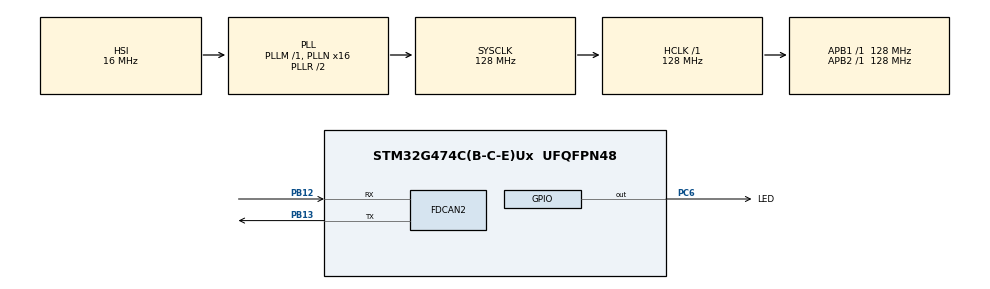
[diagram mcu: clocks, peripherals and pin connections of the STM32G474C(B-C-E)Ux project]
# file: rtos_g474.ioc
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FDCAN2.AutoRetransmission=ENABLE
FDCAN2.CalculateBaudRateNominal=1000000
FDCAN2.CalculateTimeBitNominal=1000
FDCAN2.CalculateTimeQuantumNominal=7.8125
FDCAN2.DataPrescaler=2
FDCAN2.DataSyncJumpWidth=6
FDCAN2.DataTimeSeg1=25
FDCAN2.DataTimeSeg2=6
FDCAN2.FrameFormat=FDCAN_FRAME_FD_BRS
FDCAN2.Mode=FDCAN_MODE_NORMAL
FDCAN2.NominalPrescaler=1
FDCAN2.NominalSyncJumpWidth=25
FDCAN2.NominalTimeSeg1=102
FDCAN2.NominalTimeSeg2=25
FREERTOS.Tasks01=defaultTask,24,1024,StartDefaultTask,Default,NULL,Dynamic,NULL,NULL;CANTransmitTask,24,1024,CANTransmit,Default,NULL,Static,CANTransmitTaskBuffer,CANTransmitTaskControlBlock
FREERTOS.Timers01=EnableCANTx,EnableCANTxCallback,osTimerPeriodic,Default,NULL,Dynamic,NULL
FREERTOS.configENABLE_FPU=1
FREERTOS.configMINIMAL_STACK_SIZE=1024
FREERTOS.configTOTAL_HEAP_SIZE=32768
Mcu.Family=STM32G4
Mcu.Name=STM32G474C(B-C-E)Ux
Mcu.Package=UFQFPN48
NVIC.PriorityGroup=NVIC_PRIORITYGROUP_4
NVIC.TIM6_DAC_IRQn=true\:15\:0\:false\:false\:true\:false\:false\:true\:true
NVIC.TimeBase=TIM6_DAC_IRQn
NVIC.TimeBaseIP=TIM6
PA13.Mode=Serial_Wire
PA13.Signal=SYS_JTMS-SWDIO
PA14.Mode=Serial_Wire
PA14.Signal=SYS_JTCK-SWCLK
PB12.GPIO_PuPd=GPIO_PULLUP
PB12.GPIO_Speed=GPIO_SPEED_FREQ_VERY_HIGH
PB12.Mode=FDCAN_Activate
PB12.Signal=FDCAN2_RX
PB13.GPIO_PuPd=GPIO_NOPULL
PB13.GPIO_Speed=GPIO_SPEED_FREQ_VERY_HIGH
PB13.Mode=FDCAN_Activate
PB13.Signal=FDCAN2_TX
PC6.GPIO_Label=LED
PC6.Signal=GPIO_Output
ProjectManager.HeapSize=0x200
ProjectManager.StackSize=0x400
ProjectManager.TargetToolchain=CMake
RCC.ADC12Freq_Value=128000000
RCC.ADC345Freq_Value=128000000
RCC.AHBFreq_Value=128000000
RCC.APB1Freq_Value=128000000
RCC.APB1TimFreq_Value=128000000
RCC.APB2Freq_Value=128000000
RCC.APB2TimFreq_Value=128000000
RCC.CortexFreq_Value=128000000
RCC.EXTERNAL_CLOCK_VALUE=12288000
RCC.FDCANCLockSelection=RCC_FDCANCLKSOURCE_PLL
RCC.HCLKFreq_Value=128000000
RCC.HSE_VALUE=8000000
RCC.HSI48_VALUE=48000000
RCC.HSI_VALUE=16000000
RCC.LSE_VALUE=32768
RCC.PLLN=16
RCC.SYSCLKFreq_VALUE=128000000
RCC.SYSCLKSource=RCC_SYSCLKSOURCE_PLLCLK
RCC.USBFreq_Value=128000000
RCC.VCOOutputFreq_Value=256000000
VP_FREERTOS_VS_CMSIS_V2.Mode=CMSIS_V2
VP_SYS_VS_DBSignals.Mode=DisableDeadBatterySignals
VP_SYS_VS_tim6.Mode=TIM6
board=custom

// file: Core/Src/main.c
/* USER CODE BEGIN Header */
/**
  ******************************************************************************
  * @file           : main.c
  * @brief          : Main program body
  ******************************************************************************
  * @attention
  *
  * Copyright (c) 2026 STMicroelectronics.
  * All rights reserved.
  *
  * This software is licensed under terms that can be found in the LICENSE file
  * in the root directory of this software component.
  * If no LICENSE file comes with this software, it is provided AS-IS.
  *
  ******************************************************************************
  */
/* USER CODE END Header */
#include "main.h"
#include "cmsis_os.h"
#include "fdcan.h"
#include "gpio.h"

void SystemClock_Config(void);
void MX_FREERTOS_Init(void);

int main(void)
{

  /* MCU Configuration--------------------------------------------------------*/

  /* Reset of all peripherals, Initializes the Flash interface and the Systick. */
  HAL_Init();

  /* Configure the system clock */
  SystemClock_Config();

  /* Initialize all configured peripherals */
  MX_GPIO_Init();
  MX_FDCAN2_Init();

  /* Init scheduler */
  osKernelInitialize();  /* Call init function for freertos objects (in cmsis_os2.c) */
  MX_FREERTOS_Init();

  /* Start scheduler */
  osKernelStart();

  /* We should never get here as control is now taken by the scheduler */

  /* Infinite loop */
  while (1)
  {

  }
}

void SystemClock_Config(void)
{
  RCC_OscInitTypeDef RCC_OscInitStruct = {0};
  RCC_ClkInitTypeDef RCC_ClkInitStruct = {0};

  /** Configure the main internal regulator output voltage
  */
  HAL_PWREx_ControlVoltageScaling(PWR_REGULATOR_VOLTAGE_SCALE1);

  /** Initializes the RCC Oscillators according to the specified parameters
  * in the RCC_OscInitTypeDef structure.
  */
  RCC_OscInitStruct.OscillatorType = RCC_OSCILLATORTYPE_HSI;
  RCC_OscInitStruct.HSIState = RCC_HSI_ON;
  RCC_OscInitStruct.HSICalibrationValue = RCC_HSICALIBRATION_DEFAULT;
  RCC_OscInitStruct.PLL.PLLState = RCC_PLL_ON;
  RCC_OscInitStruct.PLL.PLLSource = RCC_PLLSOURCE_HSI;
  RCC_OscInitStruct.PLL.PLLM = RCC_PLLM_DIV1;
  RCC_OscInitStruct.PLL.PLLN = 16;
  RCC_OscInitStruct.PLL.PLLP = RCC_PLLP_DIV2;
  RCC_OscInitStruct.PLL.PLLQ = RCC_PLLQ_DIV2;
  RCC_OscInitStruct.PLL.PLLR = RCC_PLLR_DIV2;
  if (HAL_RCC_OscConfig(&RCC_OscInitStruct) != HAL_OK)
  {
    Error_Handler();
  }

  /** Initializes the CPU, AHB and APB buses clocks
  */
  RCC_ClkInitStruct.ClockType = RCC_CLOCKTYPE_HCLK|RCC_CLOCKTYPE_SYSCLK
                              |RCC_CLOCKTYPE_PCLK1|RCC_CLOCKTYPE_PCLK2;
  RCC_ClkInitStruct.SYSCLKSource = RCC_SYSCLKSOURCE_PLLCLK;
  RCC_ClkInitStruct.AHBCLKDivider = RCC_SYSCLK_DIV1;
  RCC_ClkInitStruct.APB1CLKDivider = RCC_HCLK_DIV1;
  RCC_ClkInitStruct.APB2CLKDivider = RCC_HCLK_DIV1;

  if (HAL_RCC_ClockConfig(&RCC_ClkInitStruct, FLASH_LATENCY_4) != HAL_OK)
  {
    Error_Handler();
  }
}

void HAL_TIM_PeriodElapsedCallback(TIM_HandleTypeDef *htim)
{
  if (htim->Instance == TIM6)
  {
    HAL_IncTick();
  }
}

void Error_Handler(void)
{
  __disable_irq();
  while (1)
  {
  }
}

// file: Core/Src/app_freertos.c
/* USER CODE BEGIN Header */
/**
  ******************************************************************************
  * File Name          : app_freertos.c
  * Description        : Code for freertos applications
  ******************************************************************************
  * @attention
  *
  * Copyright (c) 2026 STMicroelectronics.
  * All rights reserved.
  *
  * This software is licensed under terms that can be found in the LICENSE file
  * in the root directory of this software component.
  * If no LICENSE file comes with this software, it is provided AS-IS.
  *
  ******************************************************************************
  */
/* USER CODE END Header */

#include "FreeRTOS.h"
#include "task.h"
#include "main.h"
#include "cmsis_os.h"

/* USER CODE BEGIN Includes */
#include <string.h>
#include <math.h>
#include <stdio.h>

#include "roxy.h"
#include "SEGGER_RTT.h"
#include "FreeRTOSConfig.h"
#include "fdcan.h"
/* USER CODE END Includes */

typedef StaticTask_t osStaticThreadDef_t;

/* USER CODE BEGIN PD */
_Static_assert(configTICK_RATE_HZ == 1000, "CAN scheduler assumes a 1 kHz tick");
/* USER CODE END PD */

/* USER CODE BEGIN Variables */
extern FDCAN_HandleTypeDef hfdcan2;

static struct roxy_rear_fast_t   g_fast;
static struct roxy_rear_medium_t g_medium;
static struct roxy_rear_slow_t   g_slow;

static FDCAN_TxHeaderTypeDef g_txHdr = {
  .IdType              = FDCAN_STANDARD_ID,
  .TxFrameType         = FDCAN_DATA_FRAME,
  .ErrorStateIndicator = FDCAN_ESI_ACTIVE,
  .BitRateSwitch       = FDCAN_BRS_ON,
  .FDFormat            = FDCAN_FD_CAN,
  .TxEventFifoControl  = FDCAN_NO_TX_EVENTS,
  .MessageMarker       = 0
};
/* USER CODE END Variables */
/* Definitions for defaultTask */
osThreadId_t defaultTaskHandle;
const osThreadAttr_t defaultTask_attributes = {
  .name = "defaultTask",
  .priority = (osPriority_t) osPriorityNormal,
  .stack_size = 1024 * 4
};
/* Definitions for CANTransmitTask */
osThreadId_t CANTransmitTaskHandle;
uint32_t CANTransmitTaskBuffer[ 1024 ];
osStaticThreadDef_t CANTransmitTaskControlBlock;
const osThreadAttr_t CANTransmitTask_attributes = {
  .name = "CANTransmitTask",
  .stack_mem = &CANTransmitTaskBuffer[0],
  .stack_size = sizeof(CANTransmitTaskBuffer),
  .cb_mem = &CANTransmitTaskControlBlock,
  .cb_size = sizeof(CANTransmitTaskControlBlock),
  .priority = (osPriority_t) osPriorityNormal,
};
/* Definitions for EnableCANTx */
osTimerId_t EnableCANTxHandle;
const osTimerAttr_t EnableCANTx_attributes = {
  .name = "EnableCANTx"
};

/* USER CODE BEGIN FunctionPrototypes */
void SystemViewWait();
static void     Roxy_Copy(void *dst, const void *src, size_t n);
static void     CAN_Tx(uint32_t id, const uint8_t *buf, int len, int idx);
static uint32_t len_to_dlc(uint8_t n);

void Roxy_UpdateFast(const struct roxy_rear_fast_t *s);
void Roxy_UpdateSlow(const struct roxy_rear_slow_t *s);

/* USER CODE END FunctionPrototypes */

void StartDefaultTask(void *argument);
void CANTransmit(void *argument);
void EnableCANTxCallback(void *argument);

void MX_FREERTOS_Init(void); /* (MISRA C 2004 rule 8.1) */

void MX_FREERTOS_Init(void) {
  /* USER CODE BEGIN Init */

  CoreDebug->DEMCR |= CoreDebug_DEMCR_TRCENA_Msk;
  DWT->CYCCNT = 0;
  DWT->CTRL |= DWT_CTRL_CYCCNTENA_Msk;

  // SystemView Init
  SEGGER_SYSVIEW_Conf();

  /* USER CODE END Init */

  /* Create the timer(s) */
  /* creation of EnableCANTx */
  EnableCANTxHandle = osTimerNew(EnableCANTxCallback, osTimerPeriodic, NULL, &EnableCANTx_attributes);

  /* Create the thread(s) */
  /* creation of defaultTask */
  defaultTaskHandle = osThreadNew(StartDefaultTask, NULL, &defaultTask_attributes);

  /* creation of CANTransmitTask */
  CANTransmitTaskHandle = osThreadNew(CANTransmit, NULL, &CANTransmitTask_attributes);

}

void StartDefaultTask(void *argument)
{
  /* USER CODE BEGIN StartDefaultTask */

  // SystemView TODO: (Comment this out if not using SystemView)
  SystemViewWait();

  /* Infinite loop */
  for(;;)
  {
    HAL_GPIO_TogglePin(GPIOC, LED_Pin);
    osDelay(1000);
  }
  /* USER CODE END StartDefaultTask */
}

void CANTransmit(void *argument)
{
  /* USER CODE BEGIN CANTransmit */
  HAL_FDCAN_ConfigTxDelayCompensation(&hfdcan2,
          hfdcan2.Init.DataPrescaler * hfdcan2.Init.DataTimeSeg1, 0);
  HAL_FDCAN_EnableTxDelayCompensation(&hfdcan2);
  HAL_FDCAN_Start(&hfdcan2);

  uint8_t payload[64] = {0};
  struct roxy_rear_fast_t   fast;
  struct roxy_rear_medium_t medium;
  struct roxy_rear_slow_t   slow;
  uint32_t tick = osKernelGetTickCount();

  for (uint32_t slot = 0;; slot = (slot + 1) % 100)
  {
    osDelayUntil(++tick);

    Roxy_Copy(&fast, &g_fast, sizeof fast);
    CAN_Tx(ROXY_REAR_FAST_FRAME_ID, payload,
           roxy_rear_fast_pack(payload, &fast, sizeof payload), 0);

    if (slot % 10 == 0) {
      Roxy_Copy(&medium, &g_medium, sizeof medium);
      CAN_Tx(ROXY_REAR_MEDIUM_FRAME_ID, payload,
             roxy_rear_medium_pack(payload, &medium, sizeof payload), 1);
    }

    if (slot == 1) {
      Roxy_Copy(&slow, &g_slow, sizeof slow);
      CAN_Tx(ROXY_REAR_SLOW_FRAME_ID, payload,
             roxy_rear_slow_pack(payload, &slow, sizeof payload), 2);
    }
  }
  /* USER CODE END CANTransmit */
}

/* EnableCANTxCallback function */
void EnableCANTxCallback(void *argument)
{
}

/* USER CODE BEGIN Application */
void SystemViewWait()
{
  osKernelLock();
  while (!SEGGER_RTT_HasData(1)) {}
  SEGGER_RTT_WriteNoLock(1, "SEGGER SystemView V3.52a\0\0\0\0\0\0\0", 32);
  for (uint8_t b = 0; SEGGER_RTT_ReadNoLock(1, &b, 1) != 1U || b != 1U;) {}
  SEGGER_SYSVIEW_Start();
  osKernelUnlock();
}

static void Roxy_Copy(void *dst, const void *src, size_t n)
{ taskENTER_CRITICAL(); memcpy(dst, src, n); taskEXIT_CRITICAL(); }

void Roxy_UpdateFast(const struct roxy_rear_fast_t *s)
{ Roxy_Copy(&g_fast, s, sizeof g_fast); }

void Roxy_UpdateSlow(const struct roxy_rear_slow_t *s)
{ Roxy_Copy(&g_slow, s, sizeof g_slow); }

static void CAN_Tx(uint32_t id, const uint8_t *buf, int len, int idx)
{
  (void)idx;
  if (len > 0) {
    g_txHdr.Identifier = id;
    g_txHdr.DataLength = len_to_dlc((uint8_t)len);
    if (HAL_FDCAN_GetTxFifoFreeLevel(&hfdcan2) > 0 &&
        HAL_FDCAN_AddMessageToTxFifoQ(&hfdcan2, &g_txHdr, (uint8_t *)buf) == HAL_OK)
      return;
  }
}

static uint32_t len_to_dlc(uint8_t n)
{
  static const uint32_t small[9] = {
    FDCAN_DLC_BYTES_0, FDCAN_DLC_BYTES_1, FDCAN_DLC_BYTES_2,
    FDCAN_DLC_BYTES_3, FDCAN_DLC_BYTES_4, FDCAN_DLC_BYTES_5,
    FDCAN_DLC_BYTES_6, FDCAN_DLC_BYTES_7, FDCAN_DLC_BYTES_8
  };
  if (n <= 8)  return small[n];
  if (n <= 12) return FDCAN_DLC_BYTES_12;
  if (n <= 16) return FDCAN_DLC_BYTES_16;
  if (n <= 20) return FDCAN_DLC_BYTES_20;
  if (n <= 24) return FDCAN_DLC_BYTES_24;
  if (n <= 32) return FDCAN_DLC_BYTES_32;
  if (n <= 48) return FDCAN_DLC_BYTES_48;
  return FDCAN_DLC_BYTES_64;
}
/* USER CODE END Application */
